# GD32F1x0 register map
File version: 1.0
CPU: CM3 r2p1, little endian, no MPU, no FPU, 4 interrupt priority bits
Registers are 32-bit, read-write, reset 0x0 unless marked. A register's access mark holds for its fields unless they carry their own. Offsets are from the block's base; [hi:lo] are bit positions; {n}, {i} and the like mark numbered series.

## SPI0 — Serial peripheral interface
Base 0x40013000
Same registers: SPI1 0x40003800, SPI2 0x40003C00
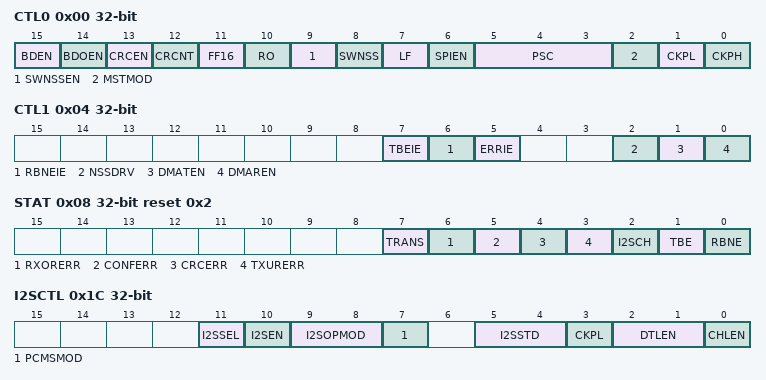
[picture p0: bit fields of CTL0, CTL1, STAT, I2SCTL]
0x00 CTL0 — control register 0
  [15] BDEN — Bidirectional enable
  [14] BDOEN — Bidirectional Transmit output enable
  [13] CRCEN — Hardware CRC calculation enable
  [12] CRCNT — CRC transfer next
  [11] FF16 — Data frame format
  [10] RO — Receive only
  [9] SWNSSEN — NSS Software Mode Selection
  [8] SWNSS — NSS Pin Selection In NSS Software Mode
  [7] LF — LSB First Mode
  [6] SPIEN — SPI enable
  [5:3] PSC — Master Clock Prescaler Selection
  [2] MSTMOD — Master selection
  [1] CKPL — Clock Polarity Selection
  [0] CKPH — Clock Phase Selection
0x04 CTL1 — control register 1
  [7] TBEIE — Tx buffer empty interrupt enable
  [6] RBNEIE — RX buffer not empty interrupt enable
  [5] ERRIE — Error interrupt enable
  [2] NSSDRV — Drive NSS Output
  [1] DMATEN — Transmit Buffer DMA Enable
  [0] DMAREN — Receive Buffer DMA Enable
0x08 STAT access per field reset 0x2 — status register
  [7] TRANS ro — Transmitting On-going Bit
  [6] RXORERR ro — Reception Overrun Error Bit
  [5] CONFERR ro — SPI Configuration error
  [4] CRCERR rw — SPI CRC Error Bit
  [3] TXURERR ro — Transmission underrun error bit
  [2] I2SCH ro — I2S channel side
  [1] TBE ro — Transmit Buffer Empty
  [0] RBNE ro — Receive Buffer Not Empty
0x0C DATA
  [15:0] DATA
0x10 CPCPOLY reset 0x7 — CRC polynomial register
  [15:0] CRCPOLY
0x14 RCRC ro — Receive CRC register
  [15:0] RCRC — CRC value of the received bytes
0x18 TCRC ro — Transmit CRC register
  [15:0] TCRC — CRC value of the transmitted bytes
0x1C I2SCTL — I2S control register
  [11] I2SSEL — I2S mode selection
  [10] I2SEN — I2S Enable
  [9:8] I2SOPMOD — I2S configuration mode
  [7] PCMSMOD — PCM frame synchronization mode
  [5:4] I2SSTD — I2S standard selection
  [3] CKPL — Idle state clock polarity
  [2:1] DTLEN — Data length
  [0] CHLEN — Channel length
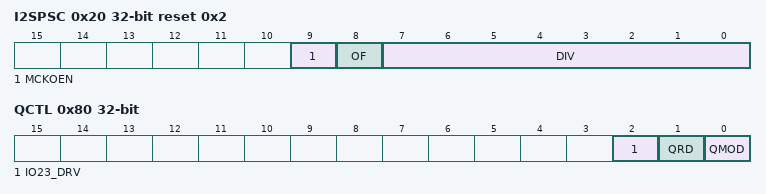
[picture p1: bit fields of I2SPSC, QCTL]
0x20 I2SPSC reset 0x2 — I2S prescaler register
  [9] MCKOEN — I2S_MCK output enable
  [8] OF — Odd factor for the prescaler
  [7:0] DIV — Dividing factor for the prescaler
0x80 QCTL — Quad wire control register
  [2] IO23_DRV — Drive IO2 and IO3 enable
  [1] QRD — Quad wire read select
  [0] QMOD — Quad wire mode enable

## SYSCFG — System configuration controller
Base 0x40010000
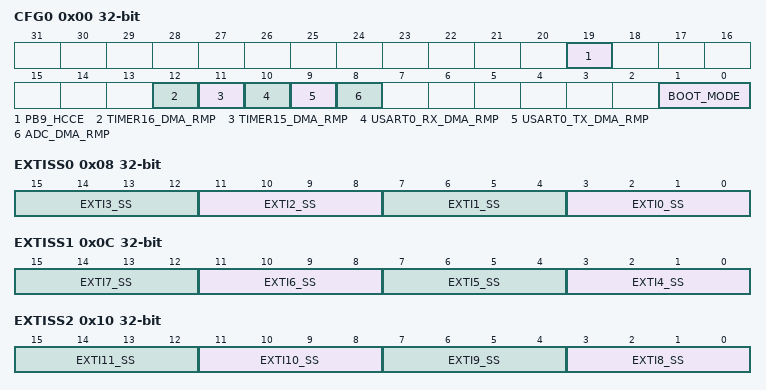
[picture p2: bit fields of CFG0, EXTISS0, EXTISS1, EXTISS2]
0x00 CFG0 access per field — System configuration register 0
  [19] PB9_HCCE rw — PB9 pin high current capability enable
  [12] TIMER16_DMA_RMP rw — Timer 16 DMA request remapping enable
  [11] TIMER15_DMA_RMP rw — Timer 15 DMA request remapping enable
  [10] USART0_RX_DMA_RMP rw — USART0_RX DMA request remapping enable
  [9] USART0_TX_DMA_RMP rw — USART0_TX DMA request remapping enable
  [8] ADC_DMA_RMP rw — ADC DMA request remapping enable
  [1:0] BOOT_MODE ro
0x04 CFG1 — System configuration register 1
  [3:1] SLCD_DECA — Decoupling capacitance connection for SLCD
0x08 EXTISS0 — EXTI sources selection register 0
  [4n+3:4n] EXTI{n}_SS (n=0..3) — EXTI {n} sources selection
0x0C EXTISS1 — EXTI sources selection register 1
  [4n-13:4n-16] EXTI{n}_SS (n=4..7) — EXTI {n} sources selection
0x10 EXTISS2 — EXTI sources selection register 2
  [4n-29:4n-32] EXTI{n}_SS (n=8..11) — EXTI {n} sources selection
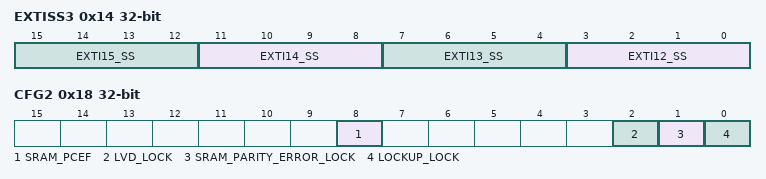
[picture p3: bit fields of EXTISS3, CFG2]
0x14 EXTISS3 — EXTI sources selection register 3
  [4n-45:4n-48] EXTI{n}_SS (n=12..15) — EXTI {n} sources selection
0x18 CFG2 — System configuration register 2
  [8] SRAM_PCEF — SRAM parity check error flag
  [2] LVD_LOCK
  [1] SRAM_PARITY_ERROR_LOCK — SRAM parity check error lock
  [0] LOCKUP_LOCK — Cortex-M3 LOCKUP output lock

## TIMER5 — Basic-timers
Base 0x40001000
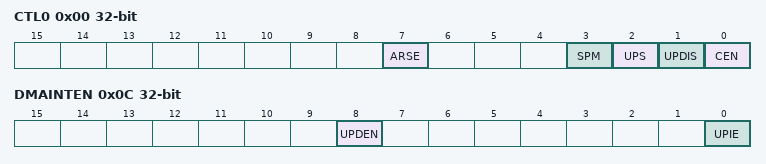
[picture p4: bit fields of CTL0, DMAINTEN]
0x00 CTL0 — control register 0
  [7] ARSE — Auto-reload shadow enable
  [3] SPM — Single pulse mode
  [2] UPS — Update source
  [1] UPDIS — Update disable
  [0] CEN — Counter enable
0x04 CTL1 — control register 1
  [6:4] MMC — Master mode control
0x0C DMAINTEN — DMA/Interrupt enable register
  [8] UPDEN — Update DMA request enable
  [0] UPIE — Update interrupt enable
0x10 INTF — status register
  [0] UPIF — Update interrupt flag
0x14 SWEVG wo — Software event generation register
  [0] UPG — Update generation
0x24 CNT — Counter register
  [15:0] CNT — current counter value
0x28 PSC — Prescaler register
  [15:0] PSC — Prescaler value of the counter clock
0x2C CAR — Counter auto reload register
  [15:0] CARL — Counter auto reload value
